# SA3_SS0_DMSS_ECCAGGR_0_ECCAGGR_CFG register map
Vendor: Texas Instruments
Peripheral module from a debugger description file (folder am62P).
Registers are 32-bit, access not given, reset 0x0 unless marked. A register's access mark holds for its fields unless they carry their own. Offsets are as the file gives them; lines under a group give offsets from that group; [hi:lo] are bit positions; {n}, {i} and the like mark numbered series; 'fields as' and 'values as' point back to an identical list; <NAME> marks a mode.

## SA3_SS0_DMSS_ECCAGGR_0_ECCAGGR_CFG
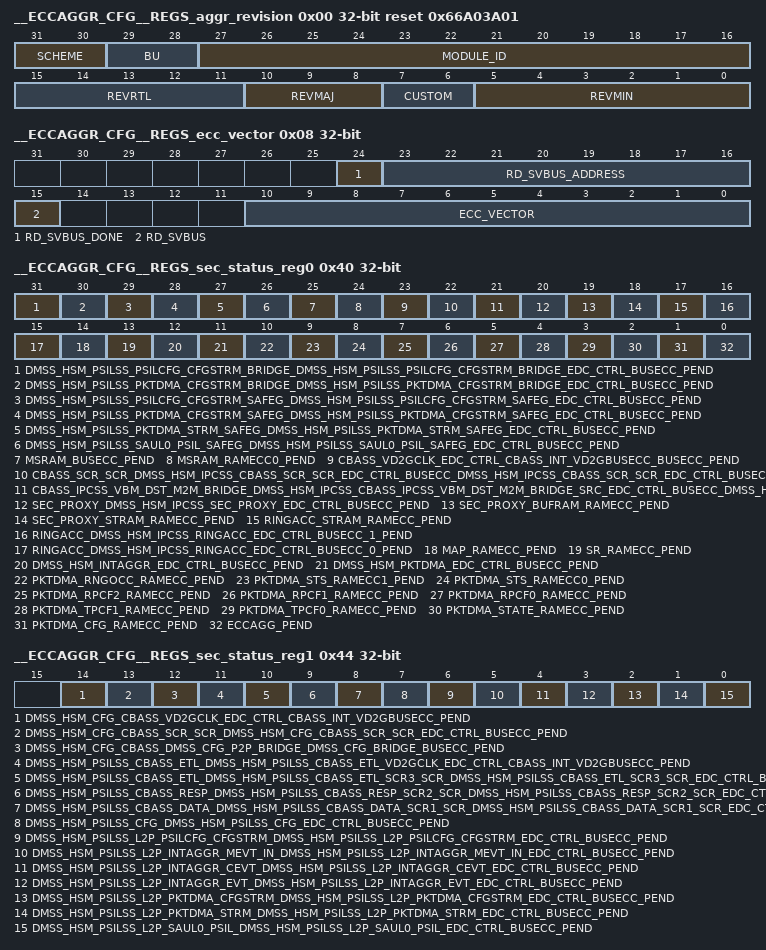
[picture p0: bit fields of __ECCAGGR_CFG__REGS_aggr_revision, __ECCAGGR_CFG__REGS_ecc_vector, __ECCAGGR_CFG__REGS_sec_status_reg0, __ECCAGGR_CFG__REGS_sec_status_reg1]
0x00 __ECCAGGR_CFG__REGS_aggr_revision ro reset 0x66A03A01 — Revision parameters
  [31:30] SCHEME
  [29:28] BU
  [27:16] MODULE_ID
  [15:11] REVRTL — RTL version
  [10:8] REVMAJ — Major version
  [7:6] CUSTOM — Custom version
  [5:0] REVMIN — Minor version
0x08 __ECCAGGR_CFG__REGS_ecc_vector — ECC Vector Register
  [24] RD_SVBUS_DONE — Status to indicate if read on serial VBUS is complete, write of any value will clear this bit. (access R/W1TC)
  [23:16] RD_SVBUS_ADDRESS rw — Read address
  [15] RD_SVBUS — Write 1 to trigger a read on the serial VBUS (access R/W1TS)
  [10:0] ECC_VECTOR rw — Value written to select the corresponding ECC RAM for control or status
0x0C __ECCAGGR_CFG__REGS_misc_status ro reset 0x2F — Misc Status
  [10:0] NUM_RAMS — Indicates the number of RAMS serviced by the ECC aggregator
0x10 __ECCAGGR_CFG__REGS_reserved_svbus rw — Reference other documents that contain the ECC RAM wrapper and EDC controller serial vbus register sets.
  [31:0] DATA — Serial VBUS register data
0x3C __ECCAGGR_CFG__REGS_sec_eoi_reg — EOI Register
  [0] EOI_WR — EOI Register (access R/W1TS)
0x40 __ECCAGGR_CFG__REGS_sec_status_reg0 — Interrupt Status Register 0
  [31] DMSS_HSM_PSILSS_PSILCFG_CFGSTRM_BRIDGE_DMSS_HSM_PSILSS_PSILCFG_CFGSTRM_BRIDGE_EDC_CTRL_BUSECC_PEND — Interrupt Pending Status for dmss_hsm_psilss_psilcfg_cfgstrm_bridge_dmss_hsm_psilss_psilcfg_cfgstrm_bridge_edc_ctrl_busecc_pend (access R/W1TS)
  [30] DMSS_HSM_PSILSS_PKTDMA_CFGSTRM_BRIDGE_DMSS_HSM_PSILSS_PKTDMA_CFGSTRM_BRIDGE_EDC_CTRL_BUSECC_PEND — Interrupt Pending Status for dmss_hsm_psilss_pktdma_cfgstrm_bridge_dmss_hsm_psilss_pktdma_cfgstrm_bridge_edc_ctrl_busecc_pend (access R/W1TS)
  [29] DMSS_HSM_PSILSS_PSILCFG_CFGSTRM_SAFEG_DMSS_HSM_PSILSS_PSILCFG_CFGSTRM_SAFEG_EDC_CTRL_BUSECC_PEND — Interrupt Pending Status for dmss_hsm_psilss_psilcfg_cfgstrm_safeg_dmss_hsm_psilss_psilcfg_cfgstrm_safeg_edc_ctrl_busecc_pend (access R/W1TS)
  [28] DMSS_HSM_PSILSS_PKTDMA_CFGSTRM_SAFEG_DMSS_HSM_PSILSS_PKTDMA_CFGSTRM_SAFEG_EDC_CTRL_BUSECC_PEND — Interrupt Pending Status for dmss_hsm_psilss_pktdma_cfgstrm_safeg_dmss_hsm_psilss_pktdma_cfgstrm_safeg_edc_ctrl_busecc_pend (access R/W1TS)
  [27] DMSS_HSM_PSILSS_PKTDMA_STRM_SAFEG_DMSS_HSM_PSILSS_PKTDMA_STRM_SAFEG_EDC_CTRL_BUSECC_PEND — Interrupt Pending Status for dmss_hsm_psilss_pktdma_strm_safeg_dmss_hsm_psilss_pktdma_strm_safeg_edc_ctrl_busecc_pend (access R/W1TS)
  [26] DMSS_HSM_PSILSS_SAUL0_PSIL_SAFEG_DMSS_HSM_PSILSS_SAUL0_PSIL_SAFEG_EDC_CTRL_BUSECC_PEND — Interrupt Pending Status for dmss_hsm_psilss_saul0_psil_safeg_dmss_hsm_psilss_saul0_psil_safeg_edc_ctrl_busecc_pend (access R/W1TS)
  [25] MSRAM_BUSECC_PEND — Interrupt Pending Status for msram_busecc_pend (access R/W1TS)
  [24] MSRAM_RAMECC0_PEND — Interrupt Pending Status for msram_ramecc0_pend (access R/W1TS)
  [23] CBASS_VD2GCLK_EDC_CTRL_CBASS_INT_VD2GBUSECC_BUSECC_PEND — Interrupt Pending Status for cbass_vd2gclk_edc_ctrl_cbass_int_vd2gbusecc_busecc_pend (access R/W1TS)
  [22] CBASS_SCR_SCR_DMSS_HSM_IPCSS_CBASS_SCR_SCR_EDC_CTRL_BUSECC_DMSS_HSM_IPCSS_CBASS_SCR_SCR_EDC_CTRL_BUSECC_PEND — Interrupt Pending Status for cbass_scr_scr_dmss_hsm_ipcss_cbass_scr_scr_edc_ctrl_busecc_dmss_hsm_ipcss_cbass_scr_scr_edc_ctrl_busecc_pend (access R/W1TS)
  [21] CBASS_IPCSS_VBM_DST_M2M_BRIDGE_DMSS_HSM_IPCSS_CBASS_IPCSS_VBM_DST_M2M_BRIDGE_SRC_EDC_CTRL_BUSECC_DMSS_HSM_IPCSS_CBASS_IPCSS_VBM_DST_M2M_BRIDGE_SRC_EDC_CTRL_BUSECC_PEND — Interrupt Pending Status for cbass_ipcss_vbm_dst_m2m_bridge_dmss_hsm_ipcss_cbass_ipcss_vbm_dst_m2m_bridge_src_edc_ctrl_busecc_dmss_hsm_ipcss_cbass_ipcss_vbm_dst_m2m_bridge_src_edc_ctrl_busecc_pend (access R/W1TS)
  [20] SEC_PROXY_DMSS_HSM_IPCSS_SEC_PROXY_EDC_CTRL_BUSECC_PEND — Interrupt Pending Status for sec_proxy_dmss_hsm_ipcss_sec_proxy_edc_ctrl_busecc_pend (access R/W1TS)
  [19] SEC_PROXY_BUFRAM_RAMECC_PEND — Interrupt Pending Status for sec_proxy_bufram_ramecc_pend (access R/W1TS)
  [18] SEC_PROXY_STRAM_RAMECC_PEND — Interrupt Pending Status for sec_proxy_stram_ramecc_pend (access R/W1TS)
  [17] RINGACC_STRAM_RAMECC_PEND — Interrupt Pending Status for ringacc_stram_ramecc_pend (access R/W1TS)
  [16] RINGACC_DMSS_HSM_IPCSS_RINGACC_EDC_CTRL_BUSECC_1_PEND — Interrupt Pending Status for ringacc_dmss_hsm_ipcss_ringacc_edc_ctrl_busecc_1_pend (access R/W1TS)
  [15] RINGACC_DMSS_HSM_IPCSS_RINGACC_EDC_CTRL_BUSECC_0_PEND — Interrupt Pending Status for ringacc_dmss_hsm_ipcss_ringacc_edc_ctrl_busecc_0_pend (access R/W1TS)
  [14] MAP_RAMECC_PEND — Interrupt Pending Status for map_ramecc_pend (access R/W1TS)
  [13] SR_RAMECC_PEND — Interrupt Pending Status for sr_ramecc_pend (access R/W1TS)
  [12] DMSS_HSM_INTAGGR_EDC_CTRL_BUSECC_PEND — Interrupt Pending Status for dmss_hsm_intaggr_edc_ctrl_busecc_pend (access R/W1TS)
  [11] DMSS_HSM_PKTDMA_EDC_CTRL_BUSECC_PEND — Interrupt Pending Status for dmss_hsm_pktdma_edc_ctrl_busecc_pend (access R/W1TS)
  [10] PKTDMA_RNGOCC_RAMECC_PEND — Interrupt Pending Status for pktdma_rngocc_ramecc_pend (access R/W1TS)
  [9] PKTDMA_STS_RAMECC1_PEND — Interrupt Pending Status for pktdma_sts_ramecc1_pend (access R/W1TS)
  [8] PKTDMA_STS_RAMECC0_PEND — Interrupt Pending Status for pktdma_sts_ramecc0_pend (access R/W1TS)
  [7] PKTDMA_RPCF2_RAMECC_PEND — Interrupt Pending Status for pktdma_rpcf2_ramecc_pend (access R/W1TS)
  [6] PKTDMA_RPCF1_RAMECC_PEND — Interrupt Pending Status for pktdma_rpcf1_ramecc_pend (access R/W1TS)
  [5] PKTDMA_RPCF0_RAMECC_PEND — Interrupt Pending Status for pktdma_rpcf0_ramecc_pend (access R/W1TS)
  [4] PKTDMA_TPCF1_RAMECC_PEND — Interrupt Pending Status for pktdma_tpcf1_ramecc_pend (access R/W1TS)
  [3] PKTDMA_TPCF0_RAMECC_PEND — Interrupt Pending Status for pktdma_tpcf0_ramecc_pend (access R/W1TS)
  [2] PKTDMA_STATE_RAMECC_PEND — Interrupt Pending Status for pktdma_state_ramecc_pend (access R/W1TS)
  [1] PKTDMA_CFG_RAMECC_PEND — Interrupt Pending Status for pktdma_cfg_ramecc_pend (access R/W1TS)
  [0] ECCAGG_PEND — Interrupt Pending Status for eccagg_pend (access R/W1TS)
0x44 __ECCAGGR_CFG__REGS_sec_status_reg1 — Interrupt Status Register 1
  [14] DMSS_HSM_CFG_CBASS_VD2GCLK_EDC_CTRL_CBASS_INT_VD2GBUSECC_PEND — Interrupt Pending Status for dmss_hsm_cfg_cbass_vd2gclk_edc_ctrl_cbass_int_vd2gbusecc_pend (access R/W1TS)
  [13] DMSS_HSM_CFG_CBASS_SCR_SCR_DMSS_HSM_CFG_CBASS_SCR_SCR_EDC_CTRL_BUSECC_PEND — Interrupt Pending Status for dmss_hsm_cfg_cbass_scr_scr_dmss_hsm_cfg_cbass_scr_scr_edc_ctrl_busecc_pend (access R/W1TS)
  [12] DMSS_HSM_CFG_CBASS_DMSS_CFG_P2P_BRIDGE_DMSS_CFG_BRIDGE_BUSECC_PEND — Interrupt Pending Status for dmss_hsm_cfg_cbass_dmss_cfg_p2p_bridge_dmss_cfg_bridge_busecc_pend (access R/W1TS)
  [11] DMSS_HSM_PSILSS_CBASS_ETL_DMSS_HSM_PSILSS_CBASS_ETL_VD2GCLK_EDC_CTRL_CBASS_INT_VD2GBUSECC_PEND — Interrupt Pending Status for dmss_hsm_psilss_cbass_etl_dmss_hsm_psilss_cbass_etl_vd2gclk_edc_ctrl_cbass_int_vd2gbusecc_pend (access R/W1TS)
  [10] DMSS_HSM_PSILSS_CBASS_ETL_DMSS_HSM_PSILSS_CBASS_ETL_SCR3_SCR_DMSS_HSM_PSILSS_CBASS_ETL_SCR3_SCR_EDC_CTRL_BUSECC_PEND — Interrupt Pending Status for dmss_hsm_psilss_cbass_etl_dmss_hsm_psilss_cbass_etl_scr3_scr_dmss_hsm_psilss_cbass_etl_scr3_scr_edc_ctrl_busecc_pend (access R/W1TS)
  [9] DMSS_HSM_PSILSS_CBASS_RESP_DMSS_HSM_PSILSS_CBASS_RESP_SCR2_SCR_DMSS_HSM_PSILSS_CBASS_RESP_SCR2_SCR_EDC_CTRL_BUSECC_PEND — Interrupt Pending Status for dmss_hsm_psilss_cbass_resp_dmss_hsm_psilss_cbass_resp_scr2_scr_dmss_hsm_psilss_cbass_resp_scr2_scr_edc_ctrl_busecc_pend (access R/W1TS)
  [8] DMSS_HSM_PSILSS_CBASS_DATA_DMSS_HSM_PSILSS_CBASS_DATA_SCR1_SCR_DMSS_HSM_PSILSS_CBASS_DATA_SCR1_SCR_EDC_CTRL_BUSECC_PEND — Interrupt Pending Status for dmss_hsm_psilss_cbass_data_dmss_hsm_psilss_cbass_data_scr1_scr_dmss_hsm_psilss_cbass_data_scr1_scr_edc_ctrl_busecc_pend (access R/W1TS)
  [7] DMSS_HSM_PSILSS_CFG_DMSS_HSM_PSILSS_CFG_EDC_CTRL_BUSECC_PEND — Interrupt Pending Status for dmss_hsm_psilss_cfg_dmss_hsm_psilss_cfg_edc_ctrl_busecc_pend (access R/W1TS)
  [6] DMSS_HSM_PSILSS_L2P_PSILCFG_CFGSTRM_DMSS_HSM_PSILSS_L2P_PSILCFG_CFGSTRM_EDC_CTRL_BUSECC_PEND — Interrupt Pending Status for dmss_hsm_psilss_l2p_psilcfg_cfgstrm_dmss_hsm_psilss_l2p_psilcfg_cfgstrm_edc_ctrl_busecc_pend (access R/W1TS)
  [5] DMSS_HSM_PSILSS_L2P_INTAGGR_MEVT_IN_DMSS_HSM_PSILSS_L2P_INTAGGR_MEVT_IN_EDC_CTRL_BUSECC_PEND — Interrupt Pending Status for dmss_hsm_psilss_l2p_intaggr_mevt_in_dmss_hsm_psilss_l2p_intaggr_mevt_in_edc_ctrl_busecc_pend (access R/W1TS)
  [4] DMSS_HSM_PSILSS_L2P_INTAGGR_CEVT_DMSS_HSM_PSILSS_L2P_INTAGGR_CEVT_EDC_CTRL_BUSECC_PEND — Interrupt Pending Status for dmss_hsm_psilss_l2p_intaggr_cevt_dmss_hsm_psilss_l2p_intaggr_cevt_edc_ctrl_busecc_pend (access R/W1TS)
  [3] DMSS_HSM_PSILSS_L2P_INTAGGR_EVT_DMSS_HSM_PSILSS_L2P_INTAGGR_EVT_EDC_CTRL_BUSECC_PEND — Interrupt Pending Status for dmss_hsm_psilss_l2p_intaggr_evt_dmss_hsm_psilss_l2p_intaggr_evt_edc_ctrl_busecc_pend (access R/W1TS)
  [2] DMSS_HSM_PSILSS_L2P_PKTDMA_CFGSTRM_DMSS_HSM_PSILSS_L2P_PKTDMA_CFGSTRM_EDC_CTRL_BUSECC_PEND — Interrupt Pending Status for dmss_hsm_psilss_l2p_pktdma_cfgstrm_dmss_hsm_psilss_l2p_pktdma_cfgstrm_edc_ctrl_busecc_pend (access R/W1TS)
  [1] DMSS_HSM_PSILSS_L2P_PKTDMA_STRM_DMSS_HSM_PSILSS_L2P_PKTDMA_STRM_EDC_CTRL_BUSECC_PEND — Interrupt Pending Status for dmss_hsm_psilss_l2p_pktdma_strm_dmss_hsm_psilss_l2p_pktdma_strm_edc_ctrl_busecc_pend (access R/W1TS)
  [0] DMSS_HSM_PSILSS_L2P_SAUL0_PSIL_DMSS_HSM_PSILSS_L2P_SAUL0_PSIL_EDC_CTRL_BUSECC_PEND — Interrupt Pending Status for dmss_hsm_psilss_l2p_saul0_psil_dmss_hsm_psilss_l2p_saul0_psil_edc_ctrl_busecc_pend (access R/W1TS)
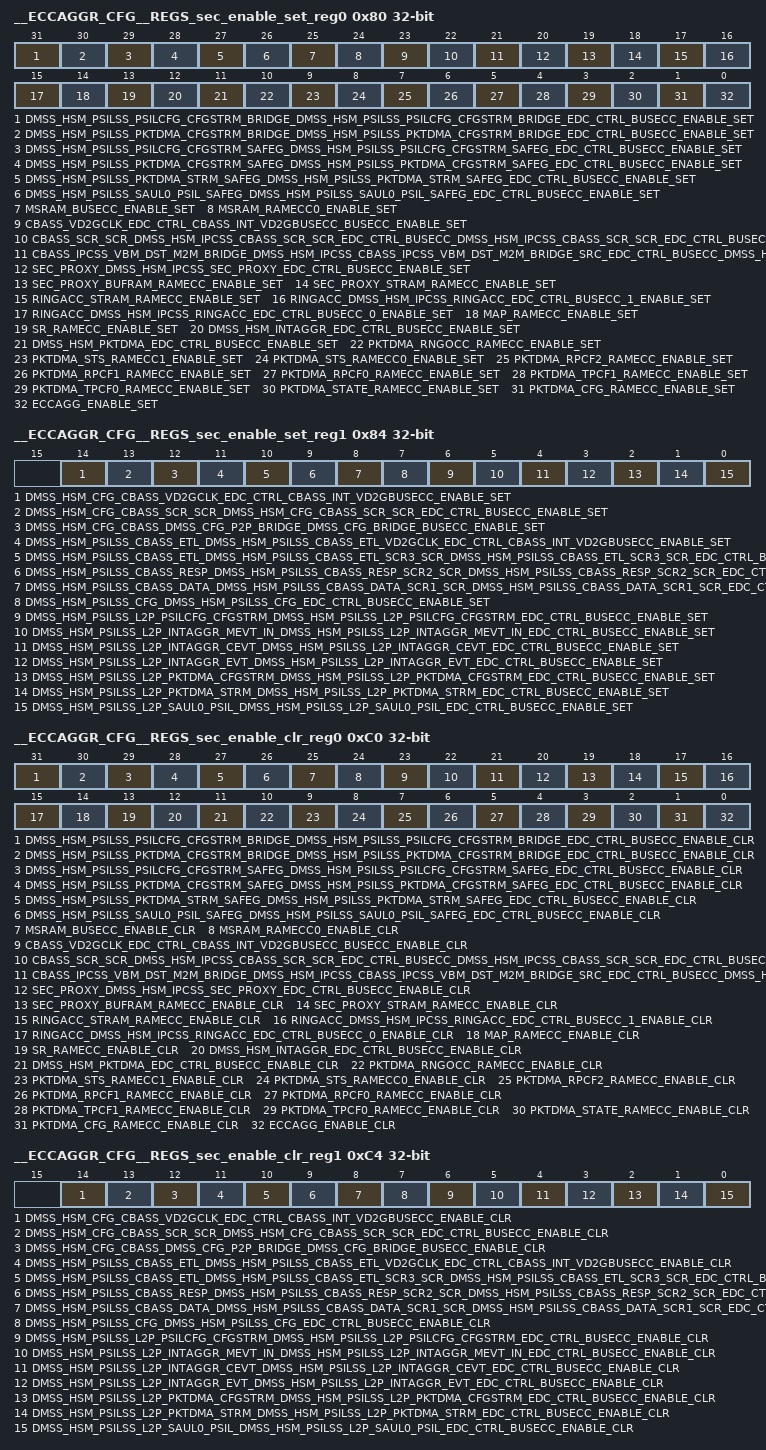
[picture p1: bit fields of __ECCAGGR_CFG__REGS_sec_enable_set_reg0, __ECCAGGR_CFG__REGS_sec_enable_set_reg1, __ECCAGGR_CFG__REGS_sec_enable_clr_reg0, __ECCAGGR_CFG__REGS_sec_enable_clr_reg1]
0x80 __ECCAGGR_CFG__REGS_sec_enable_set_reg0 — Interrupt Enable Set Register 0
  [31] DMSS_HSM_PSILSS_PSILCFG_CFGSTRM_BRIDGE_DMSS_HSM_PSILSS_PSILCFG_CFGSTRM_BRIDGE_EDC_CTRL_BUSECC_ENABLE_SET — Interrupt Enable Set Register for dmss_hsm_psilss_psilcfg_cfgstrm_bridge_dmss_hsm_psilss_psilcfg_cfgstrm_bridge_edc_ctrl_busecc_pend (access R/W1TS)
  [30] DMSS_HSM_PSILSS_PKTDMA_CFGSTRM_BRIDGE_DMSS_HSM_PSILSS_PKTDMA_CFGSTRM_BRIDGE_EDC_CTRL_BUSECC_ENABLE_SET — Interrupt Enable Set Register for dmss_hsm_psilss_pktdma_cfgstrm_bridge_dmss_hsm_psilss_pktdma_cfgstrm_bridge_edc_ctrl_busecc_pend (access R/W1TS)
  [29] DMSS_HSM_PSILSS_PSILCFG_CFGSTRM_SAFEG_DMSS_HSM_PSILSS_PSILCFG_CFGSTRM_SAFEG_EDC_CTRL_BUSECC_ENABLE_SET — Interrupt Enable Set Register for dmss_hsm_psilss_psilcfg_cfgstrm_safeg_dmss_hsm_psilss_psilcfg_cfgstrm_safeg_edc_ctrl_busecc_pend (access R/W1TS)
  [28] DMSS_HSM_PSILSS_PKTDMA_CFGSTRM_SAFEG_DMSS_HSM_PSILSS_PKTDMA_CFGSTRM_SAFEG_EDC_CTRL_BUSECC_ENABLE_SET — Interrupt Enable Set Register for dmss_hsm_psilss_pktdma_cfgstrm_safeg_dmss_hsm_psilss_pktdma_cfgstrm_safeg_edc_ctrl_busecc_pend (access R/W1TS)
  [27] DMSS_HSM_PSILSS_PKTDMA_STRM_SAFEG_DMSS_HSM_PSILSS_PKTDMA_STRM_SAFEG_EDC_CTRL_BUSECC_ENABLE_SET — Interrupt Enable Set Register for dmss_hsm_psilss_pktdma_strm_safeg_dmss_hsm_psilss_pktdma_strm_safeg_edc_ctrl_busecc_pend (access R/W1TS)
  [26] DMSS_HSM_PSILSS_SAUL0_PSIL_SAFEG_DMSS_HSM_PSILSS_SAUL0_PSIL_SAFEG_EDC_CTRL_BUSECC_ENABLE_SET — Interrupt Enable Set Register for dmss_hsm_psilss_saul0_psil_safeg_dmss_hsm_psilss_saul0_psil_safeg_edc_ctrl_busecc_pend (access R/W1TS)
  [25] MSRAM_BUSECC_ENABLE_SET — Interrupt Enable Set Register for msram_busecc_pend (access R/W1TS)
  [24] MSRAM_RAMECC0_ENABLE_SET — Interrupt Enable Set Register for msram_ramecc0_pend (access R/W1TS)
  [23] CBASS_VD2GCLK_EDC_CTRL_CBASS_INT_VD2GBUSECC_BUSECC_ENABLE_SET — Interrupt Enable Set Register for cbass_vd2gclk_edc_ctrl_cbass_int_vd2gbusecc_busecc_pend (access R/W1TS)
  [22] CBASS_SCR_SCR_DMSS_HSM_IPCSS_CBASS_SCR_SCR_EDC_CTRL_BUSECC_DMSS_HSM_IPCSS_CBASS_SCR_SCR_EDC_CTRL_BUSECC_ENABLE_SET — Interrupt Enable Set Register for cbass_scr_scr_dmss_hsm_ipcss_cbass_scr_scr_edc_ctrl_busecc_dmss_hsm_ipcss_cbass_scr_scr_edc_ctrl_busecc_pend (access R/W1TS)
  [21] CBASS_IPCSS_VBM_DST_M2M_BRIDGE_DMSS_HSM_IPCSS_CBASS_IPCSS_VBM_DST_M2M_BRIDGE_SRC_EDC_CTRL_BUSECC_DMSS_HSM_IPCSS_CBASS_IPCSS_VBM_DST_M2M_BRIDGE_SRC_EDC_CTRL_BUSECC_ENABLE_SET — Interrupt Enable Set Register for cbass_ipcss_vbm_dst_m2m_bridge_dmss_hsm_ipcss_cbass_ipcss_vbm_dst_m2m_bridge_src_edc_ctrl_busecc_dmss_hsm_ipcss_cbass_ipcss_vbm_dst_m2m_bridge_src_edc_ctrl_busecc_pend (access R/W1TS)
  [20] SEC_PROXY_DMSS_HSM_IPCSS_SEC_PROXY_EDC_CTRL_BUSECC_ENABLE_SET — Interrupt Enable Set Register for sec_proxy_dmss_hsm_ipcss_sec_proxy_edc_ctrl_busecc_pend (access R/W1TS)
  [19] SEC_PROXY_BUFRAM_RAMECC_ENABLE_SET — Interrupt Enable Set Register for sec_proxy_bufram_ramecc_pend (access R/W1TS)
  [18] SEC_PROXY_STRAM_RAMECC_ENABLE_SET — Interrupt Enable Set Register for sec_proxy_stram_ramecc_pend (access R/W1TS)
  [17] RINGACC_STRAM_RAMECC_ENABLE_SET — Interrupt Enable Set Register for ringacc_stram_ramecc_pend (access R/W1TS)
  [16] RINGACC_DMSS_HSM_IPCSS_RINGACC_EDC_CTRL_BUSECC_1_ENABLE_SET — Interrupt Enable Set Register for ringacc_dmss_hsm_ipcss_ringacc_edc_ctrl_busecc_1_pend (access R/W1TS)
  [15] RINGACC_DMSS_HSM_IPCSS_RINGACC_EDC_CTRL_BUSECC_0_ENABLE_SET — Interrupt Enable Set Register for ringacc_dmss_hsm_ipcss_ringacc_edc_ctrl_busecc_0_pend (access R/W1TS)
  [14] MAP_RAMECC_ENABLE_SET — Interrupt Enable Set Register for map_ramecc_pend (access R/W1TS)
  [13] SR_RAMECC_ENABLE_SET — Interrupt Enable Set Register for sr_ramecc_pend (access R/W1TS)
  [12] DMSS_HSM_INTAGGR_EDC_CTRL_BUSECC_ENABLE_SET — Interrupt Enable Set Register for dmss_hsm_intaggr_edc_ctrl_busecc_pend (access R/W1TS)
  [11] DMSS_HSM_PKTDMA_EDC_CTRL_BUSECC_ENABLE_SET — Interrupt Enable Set Register for dmss_hsm_pktdma_edc_ctrl_busecc_pend (access R/W1TS)
  [10] PKTDMA_RNGOCC_RAMECC_ENABLE_SET — Interrupt Enable Set Register for pktdma_rngocc_ramecc_pend (access R/W1TS)
  [9] PKTDMA_STS_RAMECC1_ENABLE_SET — Interrupt Enable Set Register for pktdma_sts_ramecc1_pend (access R/W1TS)
  [8] PKTDMA_STS_RAMECC0_ENABLE_SET — Interrupt Enable Set Register for pktdma_sts_ramecc0_pend (access R/W1TS)
  [7] PKTDMA_RPCF2_RAMECC_ENABLE_SET — Interrupt Enable Set Register for pktdma_rpcf2_ramecc_pend (access R/W1TS)
  [6] PKTDMA_RPCF1_RAMECC_ENABLE_SET — Interrupt Enable Set Register for pktdma_rpcf1_ramecc_pend (access R/W1TS)
  [5] PKTDMA_RPCF0_RAMECC_ENABLE_SET — Interrupt Enable Set Register for pktdma_rpcf0_ramecc_pend (access R/W1TS)
  [4] PKTDMA_TPCF1_RAMECC_ENABLE_SET — Interrupt Enable Set Register for pktdma_tpcf1_ramecc_pend (access R/W1TS)
  [3] PKTDMA_TPCF0_RAMECC_ENABLE_SET — Interrupt Enable Set Register for pktdma_tpcf0_ramecc_pend (access R/W1TS)
  [2] PKTDMA_STATE_RAMECC_ENABLE_SET — Interrupt Enable Set Register for pktdma_state_ramecc_pend (access R/W1TS)
  [1] PKTDMA_CFG_RAMECC_ENABLE_SET — Interrupt Enable Set Register for pktdma_cfg_ramecc_pend (access R/W1TS)
  [0] ECCAGG_ENABLE_SET — Interrupt Enable Set Register for eccagg_pend (access R/W1TS)
0x84 __ECCAGGR_CFG__REGS_sec_enable_set_reg1 — Interrupt Enable Set Register 1
  [14] DMSS_HSM_CFG_CBASS_VD2GCLK_EDC_CTRL_CBASS_INT_VD2GBUSECC_ENABLE_SET — Interrupt Enable Set Register for dmss_hsm_cfg_cbass_vd2gclk_edc_ctrl_cbass_int_vd2gbusecc_pend (access R/W1TS)
  [13] DMSS_HSM_CFG_CBASS_SCR_SCR_DMSS_HSM_CFG_CBASS_SCR_SCR_EDC_CTRL_BUSECC_ENABLE_SET — Interrupt Enable Set Register for dmss_hsm_cfg_cbass_scr_scr_dmss_hsm_cfg_cbass_scr_scr_edc_ctrl_busecc_pend (access R/W1TS)
  [12] DMSS_HSM_CFG_CBASS_DMSS_CFG_P2P_BRIDGE_DMSS_CFG_BRIDGE_BUSECC_ENABLE_SET — Interrupt Enable Set Register for dmss_hsm_cfg_cbass_dmss_cfg_p2p_bridge_dmss_cfg_bridge_busecc_pend (access R/W1TS)
  [11] DMSS_HSM_PSILSS_CBASS_ETL_DMSS_HSM_PSILSS_CBASS_ETL_VD2GCLK_EDC_CTRL_CBASS_INT_VD2GBUSECC_ENABLE_SET — Interrupt Enable Set Register for dmss_hsm_psilss_cbass_etl_dmss_hsm_psilss_cbass_etl_vd2gclk_edc_ctrl_cbass_int_vd2gbusecc_pend (access R/W1TS)
  [10] DMSS_HSM_PSILSS_CBASS_ETL_DMSS_HSM_PSILSS_CBASS_ETL_SCR3_SCR_DMSS_HSM_PSILSS_CBASS_ETL_SCR3_SCR_EDC_CTRL_BUSECC_ENABLE_SET — Interrupt Enable Set Register for dmss_hsm_psilss_cbass_etl_dmss_hsm_psilss_cbass_etl_scr3_scr_dmss_hsm_psilss_cbass_etl_scr3_scr_edc_ctrl_busecc_pend (access R/W1TS)
  [9] DMSS_HSM_PSILSS_CBASS_RESP_DMSS_HSM_PSILSS_CBASS_RESP_SCR2_SCR_DMSS_HSM_PSILSS_CBASS_RESP_SCR2_SCR_EDC_CTRL_BUSECC_ENABLE_SET — Interrupt Enable Set Register for dmss_hsm_psilss_cbass_resp_dmss_hsm_psilss_cbass_resp_scr2_scr_dmss_hsm_psilss_cbass_resp_scr2_scr_edc_ctrl_busecc_pend (access R/W1TS)
  [8] DMSS_HSM_PSILSS_CBASS_DATA_DMSS_HSM_PSILSS_CBASS_DATA_SCR1_SCR_DMSS_HSM_PSILSS_CBASS_DATA_SCR1_SCR_EDC_CTRL_BUSECC_ENABLE_SET — Interrupt Enable Set Register for dmss_hsm_psilss_cbass_data_dmss_hsm_psilss_cbass_data_scr1_scr_dmss_hsm_psilss_cbass_data_scr1_scr_edc_ctrl_busecc_pend (access R/W1TS)
  [7] DMSS_HSM_PSILSS_CFG_DMSS_HSM_PSILSS_CFG_EDC_CTRL_BUSECC_ENABLE_SET — Interrupt Enable Set Register for dmss_hsm_psilss_cfg_dmss_hsm_psilss_cfg_edc_ctrl_busecc_pend (access R/W1TS)
  [6] DMSS_HSM_PSILSS_L2P_PSILCFG_CFGSTRM_DMSS_HSM_PSILSS_L2P_PSILCFG_CFGSTRM_EDC_CTRL_BUSECC_ENABLE_SET — Interrupt Enable Set Register for dmss_hsm_psilss_l2p_psilcfg_cfgstrm_dmss_hsm_psilss_l2p_psilcfg_cfgstrm_edc_ctrl_busecc_pend (access R/W1TS)
  [5] DMSS_HSM_PSILSS_L2P_INTAGGR_MEVT_IN_DMSS_HSM_PSILSS_L2P_INTAGGR_MEVT_IN_EDC_CTRL_BUSECC_ENABLE_SET — Interrupt Enable Set Register for dmss_hsm_psilss_l2p_intaggr_mevt_in_dmss_hsm_psilss_l2p_intaggr_mevt_in_edc_ctrl_busecc_pend (access R/W1TS)
  [4] DMSS_HSM_PSILSS_L2P_INTAGGR_CEVT_DMSS_HSM_PSILSS_L2P_INTAGGR_CEVT_EDC_CTRL_BUSECC_ENABLE_SET — Interrupt Enable Set Register for dmss_hsm_psilss_l2p_intaggr_cevt_dmss_hsm_psilss_l2p_intaggr_cevt_edc_ctrl_busecc_pend (access R/W1TS)
  [3] DMSS_HSM_PSILSS_L2P_INTAGGR_EVT_DMSS_HSM_PSILSS_L2P_INTAGGR_EVT_EDC_CTRL_BUSECC_ENABLE_SET — Interrupt Enable Set Register for dmss_hsm_psilss_l2p_intaggr_evt_dmss_hsm_psilss_l2p_intaggr_evt_edc_ctrl_busecc_pend (access R/W1TS)
  [2] DMSS_HSM_PSILSS_L2P_PKTDMA_CFGSTRM_DMSS_HSM_PSILSS_L2P_PKTDMA_CFGSTRM_EDC_CTRL_BUSECC_ENABLE_SET — Interrupt Enable Set Register for dmss_hsm_psilss_l2p_pktdma_cfgstrm_dmss_hsm_psilss_l2p_pktdma_cfgstrm_edc_ctrl_busecc_pend (access R/W1TS)
  [1] DMSS_HSM_PSILSS_L2P_PKTDMA_STRM_DMSS_HSM_PSILSS_L2P_PKTDMA_STRM_EDC_CTRL_BUSECC_ENABLE_SET — Interrupt Enable Set Register for dmss_hsm_psilss_l2p_pktdma_strm_dmss_hsm_psilss_l2p_pktdma_strm_edc_ctrl_busecc_pend (access R/W1TS)
  [0] DMSS_HSM_PSILSS_L2P_SAUL0_PSIL_DMSS_HSM_PSILSS_L2P_SAUL0_PSIL_EDC_CTRL_BUSECC_ENABLE_SET — Interrupt Enable Set Register for dmss_hsm_psilss_l2p_saul0_psil_dmss_hsm_psilss_l2p_saul0_psil_edc_ctrl_busecc_pend (access R/W1TS)
0xC0 __ECCAGGR_CFG__REGS_sec_enable_clr_reg0 — Interrupt Enable Clear Register 0
  [31] DMSS_HSM_PSILSS_PSILCFG_CFGSTRM_BRIDGE_DMSS_HSM_PSILSS_PSILCFG_CFGSTRM_BRIDGE_EDC_CTRL_BUSECC_ENABLE_CLR — Interrupt Enable Clear Register for dmss_hsm_psilss_psilcfg_cfgstrm_bridge_dmss_hsm_psilss_psilcfg_cfgstrm_bridge_edc_ctrl_busecc_pend (access R/W1TC)
  [30] DMSS_HSM_PSILSS_PKTDMA_CFGSTRM_BRIDGE_DMSS_HSM_PSILSS_PKTDMA_CFGSTRM_BRIDGE_EDC_CTRL_BUSECC_ENABLE_CLR — Interrupt Enable Clear Register for dmss_hsm_psilss_pktdma_cfgstrm_bridge_dmss_hsm_psilss_pktdma_cfgstrm_bridge_edc_ctrl_busecc_pend (access R/W1TC)
  [29] DMSS_HSM_PSILSS_PSILCFG_CFGSTRM_SAFEG_DMSS_HSM_PSILSS_PSILCFG_CFGSTRM_SAFEG_EDC_CTRL_BUSECC_ENABLE_CLR — Interrupt Enable Clear Register for dmss_hsm_psilss_psilcfg_cfgstrm_safeg_dmss_hsm_psilss_psilcfg_cfgstrm_safeg_edc_ctrl_busecc_pend (access R/W1TC)
  [28] DMSS_HSM_PSILSS_PKTDMA_CFGSTRM_SAFEG_DMSS_HSM_PSILSS_PKTDMA_CFGSTRM_SAFEG_EDC_CTRL_BUSECC_ENABLE_CLR — Interrupt Enable Clear Register for dmss_hsm_psilss_pktdma_cfgstrm_safeg_dmss_hsm_psilss_pktdma_cfgstrm_safeg_edc_ctrl_busecc_pend (access R/W1TC)
  [27] DMSS_HSM_PSILSS_PKTDMA_STRM_SAFEG_DMSS_HSM_PSILSS_PKTDMA_STRM_SAFEG_EDC_CTRL_BUSECC_ENABLE_CLR — Interrupt Enable Clear Register for dmss_hsm_psilss_pktdma_strm_safeg_dmss_hsm_psilss_pktdma_strm_safeg_edc_ctrl_busecc_pend (access R/W1TC)
  [26] DMSS_HSM_PSILSS_SAUL0_PSIL_SAFEG_DMSS_HSM_PSILSS_SAUL0_PSIL_SAFEG_EDC_CTRL_BUSECC_ENABLE_CLR — Interrupt Enable Clear Register for dmss_hsm_psilss_saul0_psil_safeg_dmss_hsm_psilss_saul0_psil_safeg_edc_ctrl_busecc_pend (access R/W1TC)
  [25] MSRAM_BUSECC_ENABLE_CLR — Interrupt Enable Clear Register for msram_busecc_pend (access R/W1TC)
  [24] MSRAM_RAMECC0_ENABLE_CLR — Interrupt Enable Clear Register for msram_ramecc0_pend (access R/W1TC)
  [23] CBASS_VD2GCLK_EDC_CTRL_CBASS_INT_VD2GBUSECC_BUSECC_ENABLE_CLR — Interrupt Enable Clear Register for cbass_vd2gclk_edc_ctrl_cbass_int_vd2gbusecc_busecc_pend (access R/W1TC)
  [22] CBASS_SCR_SCR_DMSS_HSM_IPCSS_CBASS_SCR_SCR_EDC_CTRL_BUSECC_DMSS_HSM_IPCSS_CBASS_SCR_SCR_EDC_CTRL_BUSECC_ENABLE_CLR — Interrupt Enable Clear Register for cbass_scr_scr_dmss_hsm_ipcss_cbass_scr_scr_edc_ctrl_busecc_dmss_hsm_ipcss_cbass_scr_scr_edc_ctrl_busecc_pend (access R/W1TC)
  [21] CBASS_IPCSS_VBM_DST_M2M_BRIDGE_DMSS_HSM_IPCSS_CBASS_IPCSS_VBM_DST_M2M_BRIDGE_SRC_EDC_CTRL_BUSECC_DMSS_HSM_IPCSS_CBASS_IPCSS_VBM_DST_M2M_BRIDGE_SRC_EDC_CTRL_BUSECC_ENABLE_CLR — Interrupt Enable Clear Register for cbass_ipcss_vbm_dst_m2m_bridge_dmss_hsm_ipcss_cbass_ipcss_vbm_dst_m2m_bridge_src_edc_ctrl_busecc_dmss_hsm_ipcss_cbass_ipcss_vbm_dst_m2m_bridge_src_edc_ctrl_busecc_pend (access R/W1TC)
  [20] SEC_PROXY_DMSS_HSM_IPCSS_SEC_PROXY_EDC_CTRL_BUSECC_ENABLE_CLR — Interrupt Enable Clear Register for sec_proxy_dmss_hsm_ipcss_sec_proxy_edc_ctrl_busecc_pend (access R/W1TC)
  [19] SEC_PROXY_BUFRAM_RAMECC_ENABLE_CLR — Interrupt Enable Clear Register for sec_proxy_bufram_ramecc_pend (access R/W1TC)
  [18] SEC_PROXY_STRAM_RAMECC_ENABLE_CLR — Interrupt Enable Clear Register for sec_proxy_stram_ramecc_pend (access R/W1TC)
  [17] RINGACC_STRAM_RAMECC_ENABLE_CLR — Interrupt Enable Clear Register for ringacc_stram_ramecc_pend (access R/W1TC)
  [16] RINGACC_DMSS_HSM_IPCSS_RINGACC_EDC_CTRL_BUSECC_1_ENABLE_CLR — Interrupt Enable Clear Register for ringacc_dmss_hsm_ipcss_ringacc_edc_ctrl_busecc_1_pend (access R/W1TC)
  [15] RINGACC_DMSS_HSM_IPCSS_RINGACC_EDC_CTRL_BUSECC_0_ENABLE_CLR — Interrupt Enable Clear Register for ringacc_dmss_hsm_ipcss_ringacc_edc_ctrl_busecc_0_pend (access R/W1TC)
  [14] MAP_RAMECC_ENABLE_CLR — Interrupt Enable Clear Register for map_ramecc_pend (access R/W1TC)
  [13] SR_RAMECC_ENABLE_CLR — Interrupt Enable Clear Register for sr_ramecc_pend (access R/W1TC)
  [12] DMSS_HSM_INTAGGR_EDC_CTRL_BUSECC_ENABLE_CLR — Interrupt Enable Clear Register for dmss_hsm_intaggr_edc_ctrl_busecc_pend (access R/W1TC)
  [11] DMSS_HSM_PKTDMA_EDC_CTRL_BUSECC_ENABLE_CLR — Interrupt Enable Clear Register for dmss_hsm_pktdma_edc_ctrl_busecc_pend (access R/W1TC)
  [10] PKTDMA_RNGOCC_RAMECC_ENABLE_CLR — Interrupt Enable Clear Register for pktdma_rngocc_ramecc_pend (access R/W1TC)
  [9] PKTDMA_STS_RAMECC1_ENABLE_CLR — Interrupt Enable Clear Register for pktdma_sts_ramecc1_pend (access R/W1TC)
  [8] PKTDMA_STS_RAMECC0_ENABLE_CLR — Interrupt Enable Clear Register for pktdma_sts_ramecc0_pend (access R/W1TC)
  [7] PKTDMA_RPCF2_RAMECC_ENABLE_CLR — Interrupt Enable Clear Register for pktdma_rpcf2_ramecc_pend (access R/W1TC)
  [6] PKTDMA_RPCF1_RAMECC_ENABLE_CLR — Interrupt Enable Clear Register for pktdma_rpcf1_ramecc_pend (access R/W1TC)
  [5] PKTDMA_RPCF0_RAMECC_ENABLE_CLR — Interrupt Enable Clear Register for pktdma_rpcf0_ramecc_pend (access R/W1TC)
  [4] PKTDMA_TPCF1_RAMECC_ENABLE_CLR — Interrupt Enable Clear Register for pktdma_tpcf1_ramecc_pend (access R/W1TC)
  [3] PKTDMA_TPCF0_RAMECC_ENABLE_CLR — Interrupt Enable Clear Register for pktdma_tpcf0_ramecc_pend (access R/W1TC)
  [2] PKTDMA_STATE_RAMECC_ENABLE_CLR — Interrupt Enable Clear Register for pktdma_state_ramecc_pend (access R/W1TC)
  [1] PKTDMA_CFG_RAMECC_ENABLE_CLR — Interrupt Enable Clear Register for pktdma_cfg_ramecc_pend (access R/W1TC)
  [0] ECCAGG_ENABLE_CLR — Interrupt Enable Clear Register for eccagg_pend (access R/W1TC)
0xC4 __ECCAGGR_CFG__REGS_sec_enable_clr_reg1 — Interrupt Enable Clear Register 1
  [14] DMSS_HSM_CFG_CBASS_VD2GCLK_EDC_CTRL_CBASS_INT_VD2GBUSECC_ENABLE_CLR — Interrupt Enable Clear Register for dmss_hsm_cfg_cbass_vd2gclk_edc_ctrl_cbass_int_vd2gbusecc_pend (access R/W1TC)
  [13] DMSS_HSM_CFG_CBASS_SCR_SCR_DMSS_HSM_CFG_CBASS_SCR_SCR_EDC_CTRL_BUSECC_ENABLE_CLR — Interrupt Enable Clear Register for dmss_hsm_cfg_cbass_scr_scr_dmss_hsm_cfg_cbass_scr_scr_edc_ctrl_busecc_pend (access R/W1TC)
  [12] DMSS_HSM_CFG_CBASS_DMSS_CFG_P2P_BRIDGE_DMSS_CFG_BRIDGE_BUSECC_ENABLE_CLR — Interrupt Enable Clear Register for dmss_hsm_cfg_cbass_dmss_cfg_p2p_bridge_dmss_cfg_bridge_busecc_pend (access R/W1TC)
  [11] DMSS_HSM_PSILSS_CBASS_ETL_DMSS_HSM_PSILSS_CBASS_ETL_VD2GCLK_EDC_CTRL_CBASS_INT_VD2GBUSECC_ENABLE_CLR — Interrupt Enable Clear Register for dmss_hsm_psilss_cbass_etl_dmss_hsm_psilss_cbass_etl_vd2gclk_edc_ctrl_cbass_int_vd2gbusecc_pend (access R/W1TC)
  [10] DMSS_HSM_PSILSS_CBASS_ETL_DMSS_HSM_PSILSS_CBASS_ETL_SCR3_SCR_DMSS_HSM_PSILSS_CBASS_ETL_SCR3_SCR_EDC_CTRL_BUSECC_ENABLE_CLR — Interrupt Enable Clear Register for dmss_hsm_psilss_cbass_etl_dmss_hsm_psilss_cbass_etl_scr3_scr_dmss_hsm_psilss_cbass_etl_scr3_scr_edc_ctrl_busecc_pend (access R/W1TC)
  [9] DMSS_HSM_PSILSS_CBASS_RESP_DMSS_HSM_PSILSS_CBASS_RESP_SCR2_SCR_DMSS_HSM_PSILSS_CBASS_RESP_SCR2_SCR_EDC_CTRL_BUSECC_ENABLE_CLR — Interrupt Enable Clear Register for dmss_hsm_psilss_cbass_resp_dmss_hsm_psilss_cbass_resp_scr2_scr_dmss_hsm_psilss_cbass_resp_scr2_scr_edc_ctrl_busecc_pend (access R/W1TC)
  [8] DMSS_HSM_PSILSS_CBASS_DATA_DMSS_HSM_PSILSS_CBASS_DATA_SCR1_SCR_DMSS_HSM_PSILSS_CBASS_DATA_SCR1_SCR_EDC_CTRL_BUSECC_ENABLE_CLR — Interrupt Enable Clear Register for dmss_hsm_psilss_cbass_data_dmss_hsm_psilss_cbass_data_scr1_scr_dmss_hsm_psilss_cbass_data_scr1_scr_edc_ctrl_busecc_pend (access R/W1TC)
  [7] DMSS_HSM_PSILSS_CFG_DMSS_HSM_PSILSS_CFG_EDC_CTRL_BUSECC_ENABLE_CLR — Interrupt Enable Clear Register for dmss_hsm_psilss_cfg_dmss_hsm_psilss_cfg_edc_ctrl_busecc_pend (access R/W1TC)
  [6] DMSS_HSM_PSILSS_L2P_PSILCFG_CFGSTRM_DMSS_HSM_PSILSS_L2P_PSILCFG_CFGSTRM_EDC_CTRL_BUSECC_ENABLE_CLR — Interrupt Enable Clear Register for dmss_hsm_psilss_l2p_psilcfg_cfgstrm_dmss_hsm_psilss_l2p_psilcfg_cfgstrm_edc_ctrl_busecc_pend (access R/W1TC)
  [5] DMSS_HSM_PSILSS_L2P_INTAGGR_MEVT_IN_DMSS_HSM_PSILSS_L2P_INTAGGR_MEVT_IN_EDC_CTRL_BUSECC_ENABLE_CLR — Interrupt Enable Clear Register for dmss_hsm_psilss_l2p_intaggr_mevt_in_dmss_hsm_psilss_l2p_intaggr_mevt_in_edc_ctrl_busecc_pend (access R/W1TC)
  [4] DMSS_HSM_PSILSS_L2P_INTAGGR_CEVT_DMSS_HSM_PSILSS_L2P_INTAGGR_CEVT_EDC_CTRL_BUSECC_ENABLE_CLR — Interrupt Enable Clear Register for dmss_hsm_psilss_l2p_intaggr_cevt_dmss_hsm_psilss_l2p_intaggr_cevt_edc_ctrl_busecc_pend (access R/W1TC)
  [3] DMSS_HSM_PSILSS_L2P_INTAGGR_EVT_DMSS_HSM_PSILSS_L2P_INTAGGR_EVT_EDC_CTRL_BUSECC_ENABLE_CLR — Interrupt Enable Clear Register for dmss_hsm_psilss_l2p_intaggr_evt_dmss_hsm_psilss_l2p_intaggr_evt_edc_ctrl_busecc_pend (access R/W1TC)
  [2] DMSS_HSM_PSILSS_L2P_PKTDMA_CFGSTRM_DMSS_HSM_PSILSS_L2P_PKTDMA_CFGSTRM_EDC_CTRL_BUSECC_ENABLE_CLR — Interrupt Enable Clear Register for dmss_hsm_psilss_l2p_pktdma_cfgstrm_dmss_hsm_psilss_l2p_pktdma_cfgstrm_edc_ctrl_busecc_pend (access R/W1TC)
  [1] DMSS_HSM_PSILSS_L2P_PKTDMA_STRM_DMSS_HSM_PSILSS_L2P_PKTDMA_STRM_EDC_CTRL_BUSECC_ENABLE_CLR — Interrupt Enable Clear Register for dmss_hsm_psilss_l2p_pktdma_strm_dmss_hsm_psilss_l2p_pktdma_strm_edc_ctrl_busecc_pend (access R/W1TC)
  [0] DMSS_HSM_PSILSS_L2P_SAUL0_PSIL_DMSS_HSM_PSILSS_L2P_SAUL0_PSIL_EDC_CTRL_BUSECC_ENABLE_CLR — Interrupt Enable Clear Register for dmss_hsm_psilss_l2p_saul0_psil_dmss_hsm_psilss_l2p_saul0_psil_edc_ctrl_busecc_pend (access R/W1TC)
0x13C __ECCAGGR_CFG__REGS_ded_eoi_reg — EOI Register
  [0] EOI_WR — EOI Register (access R/W1TS)
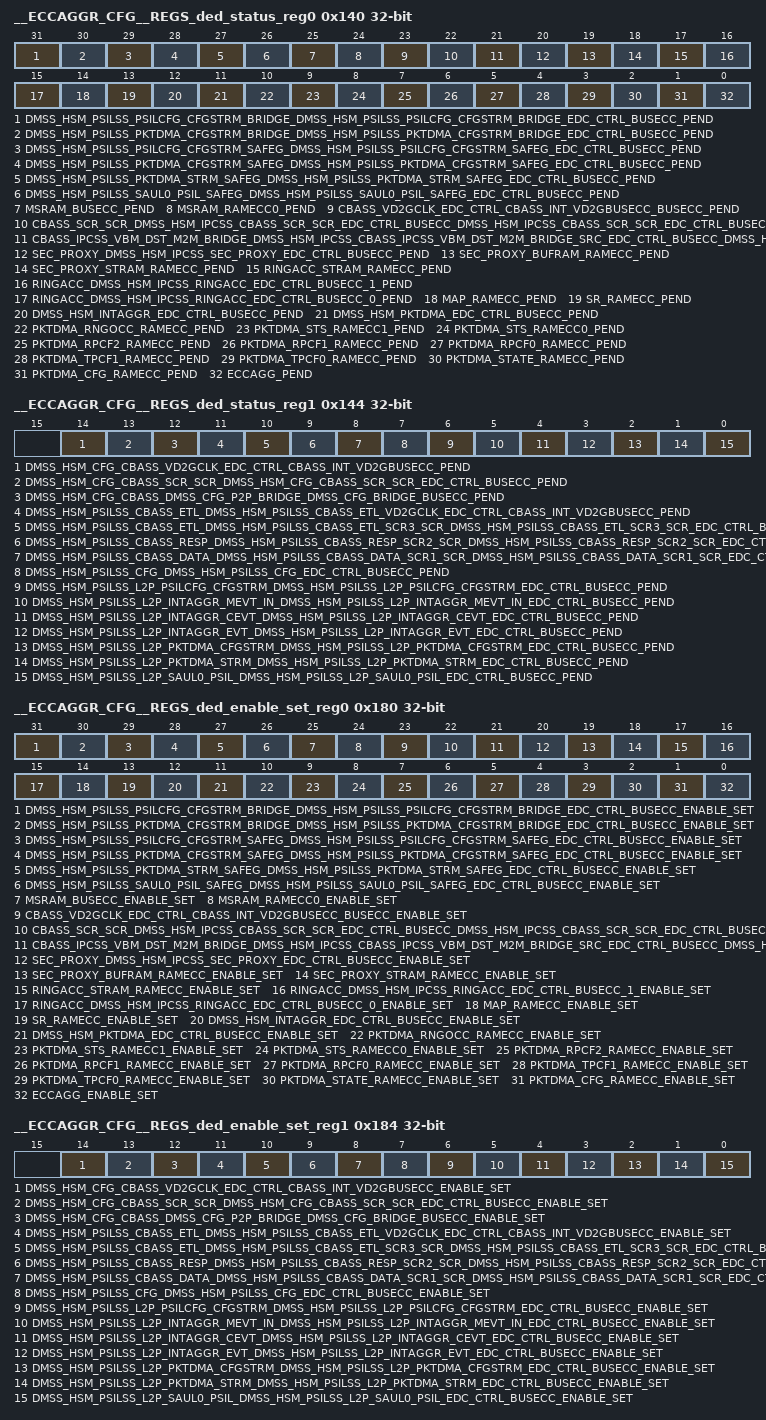
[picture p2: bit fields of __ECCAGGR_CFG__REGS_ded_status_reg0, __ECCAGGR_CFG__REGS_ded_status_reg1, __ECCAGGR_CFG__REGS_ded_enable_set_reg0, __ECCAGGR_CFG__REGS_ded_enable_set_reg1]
0x140 __ECCAGGR_CFG__REGS_ded_status_reg0 — Interrupt Status Register 0
  fields as __ECCAGGR_CFG__REGS_sec_status_reg0
0x144 __ECCAGGR_CFG__REGS_ded_status_reg1 — Interrupt Status Register 1
  fields as __ECCAGGR_CFG__REGS_sec_status_reg1
0x180 __ECCAGGR_CFG__REGS_ded_enable_set_reg0 — Interrupt Enable Set Register 0
  fields as __ECCAGGR_CFG__REGS_sec_enable_set_reg0
0x184 __ECCAGGR_CFG__REGS_ded_enable_set_reg1 — Interrupt Enable Set Register 1
  fields as __ECCAGGR_CFG__REGS_sec_enable_set_reg1
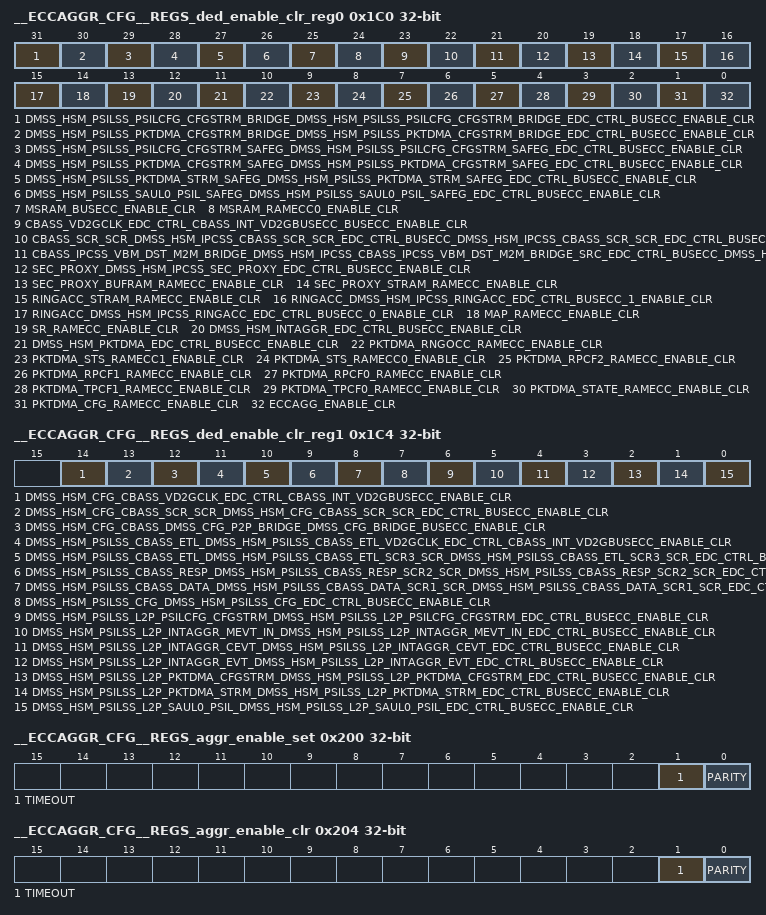
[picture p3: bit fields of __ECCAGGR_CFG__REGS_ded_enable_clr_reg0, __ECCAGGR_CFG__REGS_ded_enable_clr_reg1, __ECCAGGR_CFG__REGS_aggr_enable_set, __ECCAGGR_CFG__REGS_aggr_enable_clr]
0x1C0 __ECCAGGR_CFG__REGS_ded_enable_clr_reg0 — Interrupt Enable Clear Register 0
  fields as __ECCAGGR_CFG__REGS_sec_enable_clr_reg0
0x1C4 __ECCAGGR_CFG__REGS_ded_enable_clr_reg1 — Interrupt Enable Clear Register 1
  fields as __ECCAGGR_CFG__REGS_sec_enable_clr_reg1
0x200 __ECCAGGR_CFG__REGS_aggr_enable_set — AGGR interrupt enable set Register
  [1] TIMEOUT — interrupt enable set for svbus timeout errors (access R/W1TS)
  [0] PARITY — interrupt enable set for parity errors (access R/W1TS)
0x204 __ECCAGGR_CFG__REGS_aggr_enable_clr — AGGR interrupt enable clear Register
  [1] TIMEOUT — interrupt enable clear for svbus timeout errors (access R/W1TC)
  [0] PARITY — interrupt enable clear for parity errors (access R/W1TC)
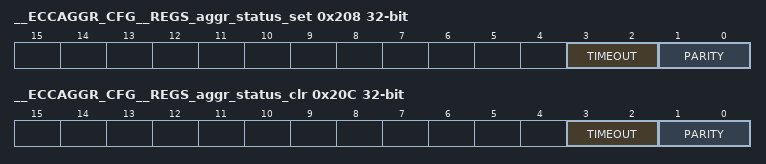
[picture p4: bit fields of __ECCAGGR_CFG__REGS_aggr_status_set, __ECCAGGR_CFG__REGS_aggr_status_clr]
0x208 __ECCAGGR_CFG__REGS_aggr_status_set — AGGR interrupt status set Register
  [3:2] TIMEOUT — interrupt status set for svbus timeout errors (access R/WI)
  [1:0] PARITY — interrupt status set for parity errors (access R/WI)
0x20C __ECCAGGR_CFG__REGS_aggr_status_clr — AGGR interrupt status clear Register
  [3:2] TIMEOUT — interrupt status clear for svbus timeout errors (access R/WD)
  [1:0] PARITY — interrupt status clear for parity errors (access R/WD)
